# TC37XPD register map
Vendor: Infineon; Series: ATVMC; File version: 100
CPU: other r0p0, little endian, MPU, FPU, vendor SysTick, 4 interrupt priority bits
Registers are 32-bit, read-write, reset 0x0 unless marked. A register's access mark holds for its fields unless they carry their own. Offsets are from the block's base; [hi:lo] are bit positions; lines under a group give offsets from that group; {n}, {i} and the like mark numbered series; 'fields as' and 'values as' point back to an identical list.

## HSSL0 — HSSL
Base 0xF0080000
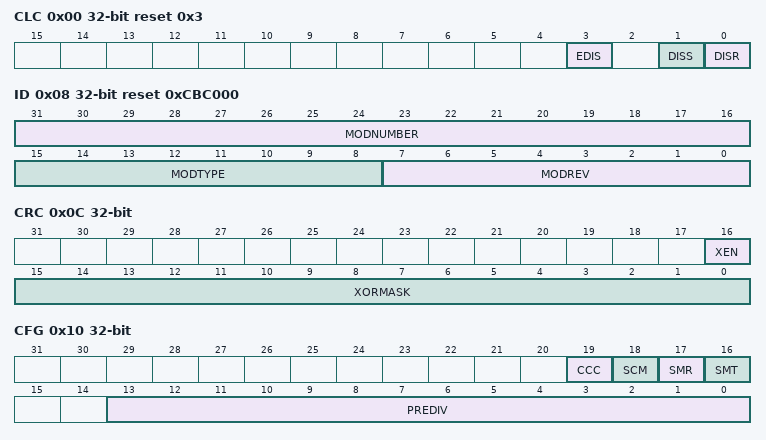
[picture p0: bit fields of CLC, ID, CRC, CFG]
0x00 CLC access per field reset 0x3 — Clock Control Register resetvalue={Application Reset:0x3}
  [3] EDIS rw — Sleep Mode Enable Control EDIS. Used to control module 8217 s sleep mode.
  [1] DISS ro — Module Disable Status Bit DISS. Bit indicates the current status of the module.
  [0] DISR rw — Module Disable Request Bit DISR. Used for enable disable control of the module.
0x08 ID ro reset 0xCBC000 (reset mask 0xFFFFFF00) — Module Identification Register resetvalue={Application Reset:0x0CBC000}
  [31:16] MODNUMBER — Module Number Value MODNUMBER. This bit field together with MODTYPE uniquely identifies a module.
  [15:8] MODTYPE — Module Type MODTYPE. This bit field is C0 H . It defines a 32 bit module.
  [7:0] MODREV — Module Revision Number MODREV. MODREV defines the module revision number. The value of a module revision starts with 01 H first revision .
0x0C CRC — CRC Control Register resetvalue={Application Reset:0x0}
  [16] XEN — Enable the Error Injection via XORMASK XEN
  [15:0] XORMASK — Value to be XORed with the Calculated CRC XORMASK. Used for error injection 160 160 test purposes.
0x10 CFG — Configuration Register resetvalue={Application Reset:0x0}
  [19] CCC — Channel Code Control CCC. Defines the coding of the channel number in the HSSL header.
  [18] SCM — Streaming Channel Mode SCM. Defines if the channel 2 is used in a streaming or command mode.
  [17] SMR — Streaming Mode Receiver SMR
  [16] SMT — Streaming Mode Transmitter SMT
  [13:0] PREDIV — Global Predivider PREDIV. Defines the down scaled module clock to be used by all channel timeout timers.
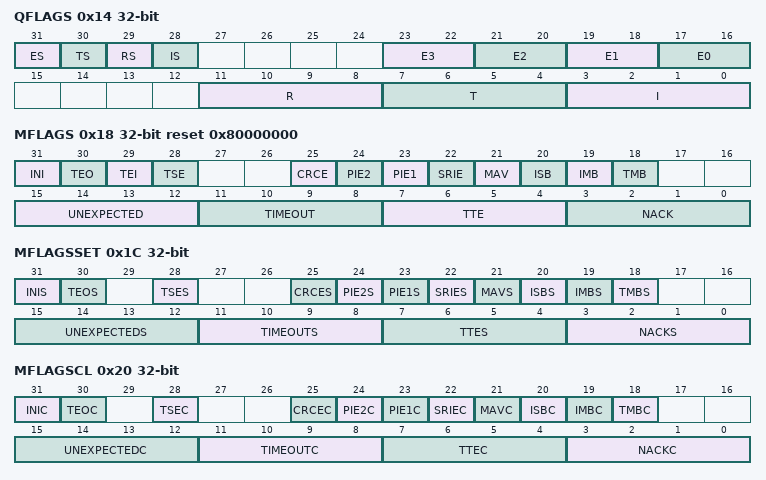
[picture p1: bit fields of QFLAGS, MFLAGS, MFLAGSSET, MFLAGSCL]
0x14 QFLAGS ro — Request Flags Register resetvalue={Application Reset:0x0}
  [31] ES — E Flag for Stream Frames ES. See the 8220 E 8221 flag description above.
  [30] TS — T Flag for Stream Frames TS. See the 8220 T 8221 flag description above.
  [29] RS — R Flag for Stream Frames RS. See the 8220 R 8221 flag description above.
  [28] IS — I Flag for Stream Frames IS. See the 8220 I 8221 flag description above.
  [23:22] E3 — Expect Flags for Activated Timeout Timer 3 E3
  [21:20] E2 — Expect Flags for Activated Timeout Timer 2 E2
  [19:18] E1 — Expect Flags for Activated Timeout Timer 1 E1
  [17:16] E0 — Expect Flags for Activated Timeout Timer 0 E0. An appropriate two bit flag is set by the hardware when a timeout timer for a channel is started. The hardware clears the appropriate flag when any response frame arrives at the initiator. In case of an unexpected response the flag UNEXPECTED is additionally set.
  [11:8] R — Request Flags for Response Frames at the Target R. After a command has been executed by the SRI SPB master an appropriate flag is being set which indicates that an ACK NACK DATA is pending.
  [7:4] T — Request Flags for Commands Arrived at Target T. These flags are set by the hardware according to the header information of a frame arrived at the target without a CRC error. They are used by the arbiter of the SRI SPB master and cleared when the appropriate command is executed.
  [3:0] I — Request Flags for Initiated Commands I. These flags are set by the corresponding channel when a WRTS command is initiated. The WRT commands are initiated via the SPB bus. The S tream commands are initiated by the module internally by the TXFIFO except for the first stream frame start which is done via the SPB bus. See MFLAGS.ISB and ISF flags.
0x18 MFLAGS ro reset 0x80000000 — Miscellaneous Flags Register resetvalue={Application Reset:0x080000000}
  [31] INI — Initialize Mode INI. Indicates if the module is in the Initialize or Run mode.
  [30] TEO — Transmit Enable Output TEO. Indicates the state of the TEO output signal of the HSSL module which drives thee CTS input signal of the HSCT module. This bit is cleared by hardware at entering the INIT and Soft Suspend state.
  [29] TEI — Transmit Enable Input TEI. Indicates the state of the TEI input signal of the HSSL module which is driven by the CTS output signal of the HSCT module. Any edge on this signal triggers an EXI interrupt. This low level signal stops the transmission of both command and response frames.
  [28] TSE — Target Stream Enable TSE. Used by the hardware to handle the single and continuous streaming. In single mode cleared by hardware after the current block transfer ends. The module ignores afterwards the incoming steam frames.
  [25] CRCE — CRC Error CRCE. Indicates if CRC checker has detected a CRC error.
  [24] PIE2 — PHY Inconsistency Error 2 Data Length Error PIE2. Indicates if HSCT to HSSL data length comparator has detected an inconsistency error.
  [23] PIE1 — PHY Inconsistency Error 1 Channel Number Code Error PIE1. Indicates if HSCT to HSSL channel number code comparator has detected an inconsistency error.
  [22] SRIE — SRI SPB Bus Access Error SRIE. Indicates an error on the SRI bus transaction ID ECC error or error acknowledge. Indicates an error on the SPB bus error acknowledge or timeout.
  [21] MAV — Memory Access Violation MAV. Indicates a memory access violation.
  [20] ISB — Initiator Stream Block Request ISB. Indicates if stream block request is pending. Set by the software to start a stream block transfer by using the MFLAGSSET.ISBS bit clear by the software possible if needed by using the MFLAGSCL.ISBC bit cleared by hardware at the end of the current block transfer in single mode but not in continuous mode.
  [19] IMB — Initiator Memory Block IMB. Selects the currently active memory block used by the initiator as a source for the streaming data with its start address and frame counter. Switching the active block in the middle of a block transfer is not allowed.
  [18] TMB — Target Memory Block TMB. Selects the currently active memory block used by the target as a target for the streaming data with its start address and frame counter. Switching the active block in the middle of a block transfer is not allowed.
  [15:12] UNEXPECTED — Unexpected Type of Frame Error UNEXPECTED. Indicates for each channel if an unexpected or inappropriate response is received. For example a NACK for a Trigger frame or DATA for WRITE frame.
  [11:8] TIMEOUT — Timeout Error TIMEOUT. Indicates for each channel if an timeout event has occurred.
  [7:4] TTE — Transaction Tag Error TTE. Indicates for each channel if a CRC correct acknowledge frame with an unexpected transaction tag number has been received.
  [3:0] NACK — Not Acknowledge Error Target Error NACK. Indicates for each channel that a target error frame has been received.
0x1C MFLAGSSET wo — Miscellaneous Flags Set Register resetvalue={Application Reset:0x0}
  [31] INIS — Initialize Mode Flag Set INIS. Writing 1 sets the corresponding bit in the MFLAGS register. Writing 0 has no effect.
  [30] TEOS — Transmit Enable Flag Set TEOS. Writing 1 sets the corresponding bit in the MFLAGS register. Writing 0 has no effect.
  [28] TSES — Target Stream Enable Flag Set TSES. Writing 1 sets the corresponding bit in the MFLAGS register. Writing 0 has no effect.
  [25] CRCES — CRC Error Flag Set CRCES. Writing 1 sets the corresponding bit in the MFLAGS register and generates an EXI interrupt if enabled in the corresponding bit of the MFLAGSEN register. Writing 0 has no effect.
  [24] PIE2S — PIE2 Error Flag Set PIE2S. Writing 1 sets the corresponding bit in the MFLAGS register and generates an EXI interrupt if enabled in the corresponding bit of the MFLAGSEN register. Writing 0 has no effect.
  [23] PIE1S — PIE1 Error Flag Set PIE1S. Writing 1 sets the corresponding bit in the MFLAGS register and generates an EXI interrupt if enabled in the corresponding bit of the MFLAGSEN register. Writing 0 has no effect
  [22] SRIES — SRI SPB Bus Access Error Flag Set SRIES. Writing 1 sets the corresponding bit in the MFLAGS register and generates an EXI interrupt if enabled in the corresponding bit of the MFLAGSEN register. Writing 0 has no effect
  [21] MAVS — MAV Flag Set MAVS. Writing 1 sets the corresponding bit in the MFLAGS register and generates an EXI interrupt if enabled in the corresponding bit of the MFLAGSEN register. Writing 0 has no effect
  [20] ISBS — Initiator Stream Block Request Set ISBS. Writing 1 sets the corresponding bit in the MFLAGS register. Writing 0 has no effect.
  [19] IMBS — Initiator Memory Block Flag Set IMBS. Writing 1 sets the corresponding bit in the MFLAGS register. Writing 0 has no effect.
  [18] TMBS — Target Memory Block Flag Set TMBS. Writing 1 sets the corresponding bit in the MFLAGS register. Writing 0 has no effect.
  [15:12] UNEXPECTEDS — Unexpected Error Flags Set UNEXPECTEDS. Writing 1 sets the corresponding bit in the MFLAGS register and triggers the ERR interrupt for the corresponding channel if enabled in the MFLAGSEN register. Writing 0 has no effect.
  [11:8] TIMEOUTS — Timeout Error Flags Set TIMEOUTS. Writing 1 sets the corresponding bit in the MFLAGS register and triggers the ERR interrupt for the corresponding channel if enabled in the MFLAGSEN register. Writing 0 has no effect.
  [7:4] TTES — Transaction Tag Error Flags Set TTES. Writing 1 sets the corresponding bit in the MFLAGS register and triggers the ERR interrupt for the corresponding channel if enabled in the MFLAGSEN register. Writing 0 has no effect.
  [3:0] NACKS — NACK Flags Set NACKS. Writing 1 sets the corresponding bit in the MFLAGS register and triggers the ERR interrupt for the corresponding channel if enabled in the MFLAGSEN register. Writing 0 has no effect.
0x20 MFLAGSCL wo — Miscellaneous Flags Clear Register resetvalue={Application Reset:0x0}
  [31] INIC — Initialize Mode Flag Clear INIC. Writing 1 clears the corresponding bit in the MFLAGS register. Writing 0 has no effect.
  [30] TEOC — Transmit Enable Flag Clear TEOC. Writing 1 clears the corresponding bit in the MFLAGS register. Writing 0 has no effect.
  [28] TSEC — Target Stream Enable Flag Clear TSEC. Writing 1 sets the corresponding bit in the MFLAGS register. Writing 0 has no effect.
  [25] CRCEC — CRC Error Flag Clear CRCEC. Writing 1 clears the corresponding bit in the MFLAGS register. Writing 0 has no effect.
  [24] PIE2C — PIE2 Error Flag Clear PIE2C. Writing 1 clears the corresponding bit in the MFLAGS register. Writing 0 has no effect.
  [23] PIE1C — PIE1 Error Flag Clear PIE1C. Writing 1 clears the corresponding bit in the MFLAGS register. Writing 0 has no effect
  [22] SRIEC — SRI SPB Bus Access Error Flag Clear SRIEC. Writing 1 clears the corresponding bit in the MFLAGS register. Writing 0 has no effect
  [21] MAVC — MAV Flag Clear MAVC. Writing 1 clears the corresponding bit in the MFLAGS register. Writing 0 has no effect
  [20] ISBC — Initiator Stream Block Request Clear ISBC. Writing 1 clears the corresponding bit in the MFLAGS register. Writing 0 has no effect.
  [19] IMBC — Initiator Memory Block Flag Clear IMBC. Writing 1 clears the corresponding bit in the MFLAGS register. Writing 0 has no effect.
  [18] TMBC — Target Memory Block Flag Clear TMBC. Writing 1 clears the corresponding bit in the MFLAGS register. Writing 0 has no effect.
  [15:12] UNEXPECTEDC — Unexpected Error Flags Clear UNEXPECTEDC. Writing 1 clears the corresponding bit in the MFLAGS register. Writing 0 has no effect.
  [11:8] TIMEOUTC — Timeout Error Flags Clear TIMEOUTC. Writing 1 clears the corresponding bit in the MFLAGS register. Writing 0 has no effect.
  [7:4] TTEC — Transaction Tag Error Flags Clear TTEC. Writing 1 clears the corresponding bit in the MFLAGS register. Writing 0 has no effect.
  [3:0] NACKC — NACK Flags Clear NACKC. Writing 1 clears the corresponding bit in the MFLAGS register. Writing 0 has no effect.
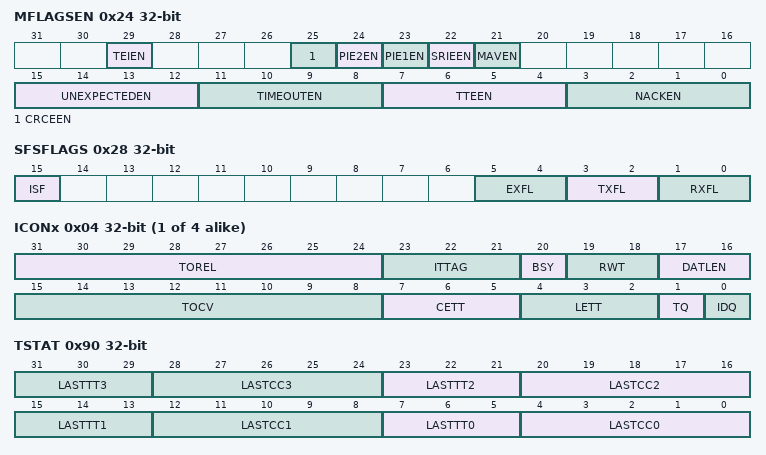
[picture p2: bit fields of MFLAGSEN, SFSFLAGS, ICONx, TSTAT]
0x24 MFLAGSEN — Flags Enable Register resetvalue={Application Reset:0x0}
  [29] TEIEN — TEI Enable Bit TEIEN. Used to enable the interrupt associated to the corresponding bit in the MFLAGS register.
  [25] CRCEEN — CRC Error Enable Bit CRCEEN. Used to enable the error interrupt associated to the corresponding bit in the MFLAGS register.
  [24] PIE2EN — PIE2 Error Enable Bit PIE2EN. Used to enable the error interrupt associated to the corresponding bit in the MFLAGS register.
  [23] PIE1EN — PIE1 Error Enable Bit PIE1EN. Used to enable the error interrupt associated to the corresponding bit in the MFLAGS register.
  [22] SRIEEN — SRI SPB Bus Access Error Enable Bit SRIEEN. Used to enable the error interrupt associated to the corresponding bit in the MFLAGS register.
  [21] MAVEN — MAV Enable Bit MAVEN. Used to enable the interrupt associated to the corresponding bit in the MFLAGS register.
  [15:12] UNEXPECTEDEN — Unexpected Error Enable Bits UNEXPECTEDEN. Used to enable the error interrupt associated to the corresponding bit in the MFLAGS register.
  [11:8] TIMEOUTEN — Timeout Error Enable Bits TIMEOUTEN. Used to enable the error interrupt associated to the corresponding bit in the MFLAGS register.
  [7:4] TTEEN — Transaction Tag Error Enable Bits TTEEN. Used to enable the error interrupt associated to the corresponding bit in the MFLAGS register.
  [3:0] NACKEN — Not Acknowledge Error Enable Bits NACKEN. Used to enable the error interrupt associated to the corresponding bit in the MFLAGS register.
0x28 SFSFLAGS ro — Stream FIFOs Status Flags Register resetvalue={Application Reset:0x0}
  [15] ISF — Initiator Stream Frame Request ISF. Indicates if stream TXFIFO request is pending. Set and cleared by the TXFIFO.
  [5:4] EXFL — Stream Expect FIFO Filling Level EXFL. Indicates the filling level of the FIFO with granularity of 32 bytes one stream frame payload size .
  [3:2] TXFL — Stream TxFIFO Filling Level TXFL. Indicates the filling level of the FIFO with granularity of 32 bytes one stream frame payload size .
  [1:0] RXFL — Stream RxFIFO Filling Level RXFL. Indicates the filling level of the FIFO with granularity of 32 bytes one stream frame payload size .
{0x30+0x10*i} I[{i}] (i=0..3) group
  0x00 IWDx — Initiator Write Data Register 0 resetvalue={Application Reset:0x0}
    [31:0] DATA — Data Part of the Payload of a Write Frame DATA. For 8 bit and16 bit write command frames the whole frame payload width of 32 bit is automatically filled with copies of the lower 8 bits or 16 bits of the register.
  0x04 ICONx access per field — Initiator Control Data Register 0 resetvalue={Application Reset:0x0}
    [31:24] TOREL rw — Time Out Reload Value TOREL. Defines the duration of the timeout in units of prescaled clock periods. This parameter is valid both in command and stream mode of the channel 2.
    [23:21] ITTAG ro — Initiator Transaction Tag ITTAG. This bit displays the current value of the three bit counter generating the new transaction tag value.
    [20] BSY ro — Channel Busy BSY
    [19:18] RWT rw — Read Write Trigger Command Type RWT. Defines if the write to the IRWA register will trigger read write or trigger request.
    [17:16] DATLEN rw — Data Length DATLEN. Defines the length of the data in bits of the write and read command.
    [15:8] TOCV ro — Time Out Current Value TOCV
    [7:5] CETT ro — Currently Expected Transaction Tag CETT
    [4:2] LETT ro — Last Error Transaction Tag LETT
    [1] TQ wo — Trigger Request TQ. This bit provides an alternative way to request a trigger frame without having to write to the channel address register. Reads always 0. Write of 1 commences a request. In case of parallel write of 1 to TQ and IDQ the IDQ request has higher priority.
    [0] IDQ wo — Read ID Request IDQ. This bit provides the only way to request a read ID frame. Reads always 0. Write of 1 commences a request. In case of parallel write of 1 to TQ and IDQ the IDQ request has higher priority.
  0x08 IRWAx — Initiator Read Write Address Register 0 resetvalue={Application Reset:0x0}
    [31:0] ADDRESS — Address Part of the Payload of a Write Frame ADDRESS. Writing to this registers triggers transmission of a Write Frame. The address must be aligned according to the data width byte addresses for 8 bit data half word addresses for 16 bit data word addresses for 32 bit data.
  0x0C IRDx ro — Initiator Read Data Register 0 resetvalue={Application Reset:0x0}
    [31:0] DATA — Data Delivered by a Read Response Frame DATA
{0x70+8i} T[{i}] (i=0..3) group
  0x00 TCDi ro — Target Current Data Register 0 resetvalue={Application Reset:0x0}
    [31:0] D — Data Part of the Payload of a Write Command Frame or Read Data of a Read Command Frame D
  0x04 TCAi ro — Target Current Address Register 0 resetvalue={Application Reset:0x0}
    [31:0] A — Address Part of the Payload of a Write Command Frame or a Read Command Frame or ID Frame A
0x90 TSTAT ro — Target Status Register resetvalue={Application Reset:0x0}
  [8n+7:8n+5] LASTTT{n} (n=0..3) — Last Transaction Tag LASTTT3. Indicates the transaction tag of the latest command or stream frame for the corresponding channel.
  [8n+4:8n] LASTCC{n} (n=0..3) — Last Command Code LASTCC3. Indicates the latest command code from the header for the corresponding channel.
0x94 TIDADD — Target ID Address Register resetvalue={Application Reset:0x0}
  [31:0] A — Address Pointer A. Address pointer containing the address of the memory location containing the unique ID data.
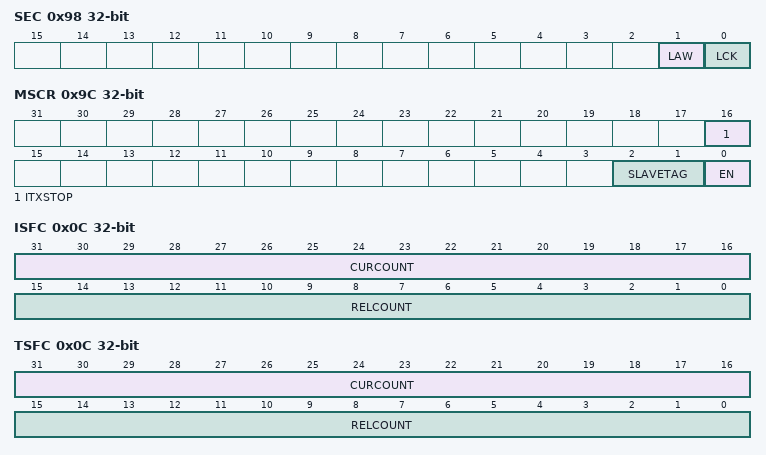
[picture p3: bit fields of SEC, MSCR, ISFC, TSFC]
0x98 SEC — Security Control Register resetvalue={Application Reset:0x0}
  [1] LAW — Lock the Address Windows Registers LAW. This bit field shows if the Address Window Registers AWSTARTx AWENDx AR and TIDADD are locked or not. If locked the properties of the address windows cannot be changed any more. This bit can only be written by an access from the HSM master TAG 000011B . A write operation performed by any other master is ignored and the bit remains unchanged.
  [0] LCK — Lock the HSSL Module LCK. Setting this bit field prevents the MFLAGS.INI bit to be cleared that is prevents to leave the INIT state and go to RUN mode. If INIT bit has already been cleared it is possible to set it but not to clear it afterwards. This bit can only be written by an access from the HSM master TAG 000011B . A write operation performed by any other master is ignored and the bit remains unchanged.
0x9C MSCR — Multi Slave Control Register resetvalue={Application Reset:0x0}
  [16] ITXSTOP — Initiator Transmission Stop ITXSTOP. This bit is intended to be set or cleared by the master in a multi slave operation by using 16 bit write command frames. MSCR.ITXSTOP functionality can be activated only if MSCR.EN 160 160 1 otherwise it is ignored. Setting this bit stops the arbitration and transmission of new command and stream frames of the initiator but does not stop the ongoing frames.
  [2:1] SLAVETAG — Slave Tag SLAVETAG. The master uses this bit field to define the current slave it sends to and receives from. The slave uses this bit field to pass through only the relevant incoming frames and to tag its own transmit frames. This tag is injected in the header by the Slave Tag Translator block and used for filtering in Slave Tag Filter Block.
  [0] EN — Multi Slave Mode Enable EN. This bit enables the multi slave mode of operation of the HSSL module.
0xA0 IS group
  {0x0+4j} ISSAx[{j}] (j=0..1) — Initiator Stream Start Address Register resetvalue={Application Reset:0x0}
    [31:5] START — Start Address for the Memory Range START. Aligned on 256 bit limit stream frame payload size .
  0x08 ISCA ro — Initiator Stream Current Address Register resetvalue={Application Reset:0x0}
    [31:5] CURR — Address of the Memory Location for the Current Transfer CURR. Aligned on 256 bit limit stream frame payload size .
  0x0C ISFC access per field — Initiator Stream Frame Count Register resetvalue={Application Reset:0x0}
    [31:16] CURCOUNT ro — Current Count Number CURCOUNT. Displays the current count number which is generated by down counting from the RELCOUNT value. Bit field length depends on application requirements.
    [15:0] RELCOUNT rw — Reload Count Number RELCOUNT. Contains the number of frames to transfer per memory block. Bit field length depends on application requirements.
0xB0 TS group
  {0x0+4j} TSSAx[{j}] (j=0..1) — Target Stream Start Address Register 0 resetvalue={Application Reset:0x0}
    [31:5] ADDR — Start Address for the Memory Range ADDR. Aligned on 256 bit or 32 byte limit stream frame payload size .
  0x08 TSCA ro — Target Stream Current Address Register resetvalue={Application Reset:0x0}
    [31:5] CURR — Address of the Memory Location for the Current Transfer CURR. Aligned on 256 bit or 32 byte limit stream frame payload size .
  0x0C TSFC access per field — Target Stream Frame Count Register resetvalue={Application Reset:0x0}
    fields as IS.ISFC
{0xC0+8i} AW[{i}] (i=0..3) group
  0x00 AWSTARTi — Access Window Start Register 0 resetvalue={Application Reset:0x0}
    [31:8] AWS — Access Window Start Address AWS. This bit field defines the upper 24 bits of the start address of the corresponding access window. This results in a granularity of 256 bytes for the start address.
  0x04 AWENDi — Access Window End Register 0 resetvalue={Application Reset:0x0}
    [31:8] AWE — Access Window End Address AWE. This bit field defines the upper 24 bits of the end address of the corresponding access window. This results in a granularity of 256 bytes for the end address.
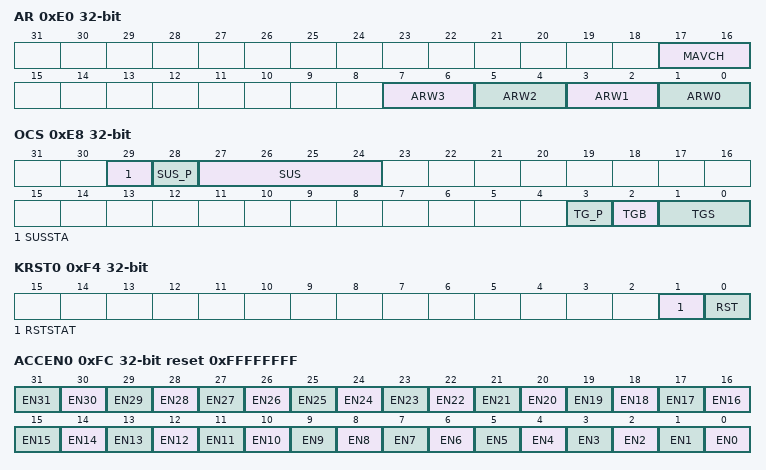
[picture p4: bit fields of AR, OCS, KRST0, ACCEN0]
0xE0 AR access per field — Access Rules Register resetvalue={Application Reset:0x0}
  [17:16] MAVCH ro — Memory Access Violation Channel MAVCH. This bit field shows the number of the latest channel that attempted a not allowed access.
  [2n+1:2n] ARW{n} rw (n=0..3) — Access Rule for Window 3 ARW3
0xE8 OCS access per field — OCDS Control and Status resetvalue={Debug Reset:0x0}
  [29] SUSSTA ro — Suspend State SUSSTA
  [28] SUS_P wo — SUS Write Protection SUS P. SUS is only written when SUS P is 1 otherwise unchanged. Read as 0.
  [27:24] SUS rw — OCDS Suspend Control SUS. Controls the sensitivity to the suspend signal coming from the OCDS Trigger Switch OTGS
  [3] TG_P wo — TGS TGB Write Protection TG P. TGS and TGB are only written when TG P is 1 otherwise unchanged. Read as 0.
  [2] TGB rw — OTGB0 1 Bus Select TGB
  [1:0] TGS rw — Trigger Set for OTGB0 1 TGS
0xEC KRSTCLR wo — Kernel Reset Status Clear Register resetvalue={Application Reset:0x0}
  [0] CLR — Kernel Reset Status Clear CLR. Read always as 0.
0xF0 KRST1 — Kernel Reset Register 1 resetvalue={Application Reset:0x0}
  [0] RST — Kernel Reset RST. This reset bit can be used to request for a kernel reset. The kernel reset will be executed if the reset bits of both kernel reset registers is set. The RST bit will be cleared re set to 180 0 180 by the BPI FPI after the kernel reset was executed.
0xF4 KRST0 access per field — Kernel Reset Register 0 resetvalue={Application Reset:0x0}
  [1] RSTSTAT ro — Kernel Reset Status RSTSTAT. This bit indicates wether a kernel reset was executed or not. This bit is set by the BPI FPI after the execution of a kernel reset in the same clock cycle both reset bits. This bit can be cleared by writing with 180 1 180 to the CLR bit in the related KRSTCLR register.
  [0] RST rw — Kernel Reset RST. This reset bit can be used to request for a kernel reset. The kernel reset will be executed if the reset bits of both kernel registers are set. The RST bit will be cleared re set to 180 0 180 by the BPI FPI after the kernel reset was executed.
0xFC ACCEN0 reset 0xFFFFFFFF — Access Enable Register 0 resetvalue={Application Reset:0x0FFFFFFFF}
  [n] EN{n} (n=0..31) — Access Enable for Master TAG ID 31 EN31. This bit enables write access to the module kernel addresses for transactions with the Master TAG ID y
